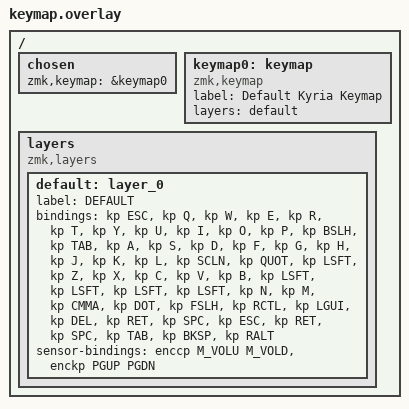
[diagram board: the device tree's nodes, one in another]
#include <behaviors.dtsi>
#include <dt-bindings/zmk/keys.h>
#include <dt-bindings/zmk/matrix-transform.h>

/ {
	chosen {
		zmk,keymap = &keymap0;
	};
	
	keymap0: keymap {
		compatible = "zmk,keymap";
		label ="Default Kyria Keymap";
		layers = <&default>;
	};

	layers {
		compatible = "zmk,layers";

		default: layer_0 {
			label = "DEFAULT";
// ---------------------------------------------------------------------------------------------------------------------------------
// |  ESC  |  Q  |  W  |  E   |  R   |  T   |                                          |  Y   |  U    |  I    |  O   |   P   |   \  |
// |  TAB  |  A  |  S  |  D   |  F   |  G   |                                          |  H   |  J    |  K    |  L   |   ;   |   '  |
// | SHIFT |  Z  |  X  |  C   |  V   |  B   | L SHIFT | L SHIFT |  | L SHIFT | L SHIFT |  N   |  M    |  ,    |  .   |   /   | CTRL |
//                     | GUI  | DEL  | RET  |  SPACE  |   ESC   |  |   RET   |  SPACE  | TAB  | BSPC  | R-ALT |
			bindings = <
	&kp ESC  &kp Q &kp W &kp E &kp R &kp T                                            &kp Y &kp U  &kp I    &kp O   &kp P    &kp BSLH
	&kp TAB  &kp A &kp S &kp D &kp F &kp G                                            &kp H &kp J  &kp K    &kp L   &kp SCLN &kp QUOT
	&kp LSFT &kp Z &kp X &kp C &kp V &kp B &kp LSFT &kp LSFT        &kp LSFT &kp LSFT &kp N &kp M  &kp CMMA &kp DOT &kp FSLH &kp RCTL
	              &kp LGUI &kp DEL &kp RET &kp SPC &kp ESC            &kp RET  &kp SPC  &kp TAB &kp BKSP &kp RALT
			>;

			sensor-bindings = <&enccp M_VOLU M_VOLD &enckp PGUP PGDN>;
		};
	};
};
